AUTOSAR XML (schema 4-2-2)
package /ComponentTypes
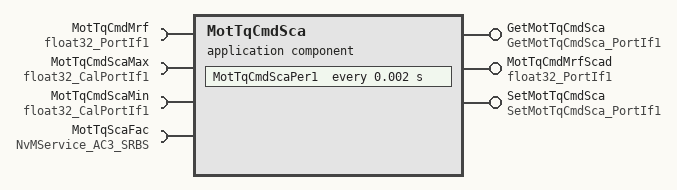
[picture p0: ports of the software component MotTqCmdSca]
  application sw component type MotTqCmdSca
    provide port GetMotTqCmdSca: server-com-spec{operation=Oper, queue-length=1}, provided-interface=GetMotTqCmdSca_PortIf1
    provide port MotTqCmdMrfScad: nonqueued-sender-com-spec{data-element=Val, init-value=0}, provided-interface=float32_PortIf1
    provide port SetMotTqCmdSca: server-com-spec{operation=Oper, queue-length=1}, provided-interface=SetMotTqCmdSca_PortIf1
    4 x require port:
      MotTqCmdMrf: nonqueued-receiver-com-spec{data-element=Val, filter=data-filter-type=ALWAYS, init-value=0}, required-interface=float32_PortIf1
      MotTqCmdScaMax: parameter-require-com-spec{init-value=1.1, parameter=Val}, required-interface=float32_CalPortIf1
      MotTqCmdScaMin: parameter-require-com-spec{init-value=0.9, parameter=Val}, required-interface=float32_CalPortIf1
      MotTqScaFac: required-com-specs=[EraseBlock, GetErrorStatus, InvalidateNvBlock, ReadBlock, SetRamBlockStatus, WriteBlock], required-interface=NvMService_AC3_SRBS
    behavior MotTqCmdSca_InternalBehavior
      ar-typed-per-instance-memorys:
        data MotTqScaFac: sw-calibration-access=READ-ONLY, type=float32
      operation invoked event OIT_GetMotTqCmdSca_Oper_GetMotTqCmdSca_Oper: start-on-event=GetMotTqCmdSca_Oper, operation=GetMotTqCmdSca.Oper
      init event MotTqCmdSca_InitEvent: start-on-event=MotTqCmdScaInit1
      timing event TMT_MotTqCmdScaPer1: start-on-event=MotTqCmdScaPer1, period=0.002
      operation invoked event OIT_SetMotTqCmdSca_Oper_SetMotTqCmdSca_Oper: start-on-event=SetMotTqCmdSca_Oper, operation=SetMotTqCmdSca.Oper
      4 x runnable:
        GetMotTqCmdSca_Oper
        MotTqCmdScaInit1
          sync call SC_MotTqScaFac_GetErrorStatus: operation=MotTqScaFac.GetErrorStatus, timeout=0
          sync call SC_MotTqScaFac_SetRamBlockStatus: operation=MotTqScaFac.SetRamBlockStatus, timeout=0
        MotTqCmdScaPer1: minimum-start-interval=0.002
          data-receive-point-by-arguments:
            access REC_MotTqCmdMrf_Val: accessed-variable=MotTqCmdMrf.Val
          data-send-points:
            access SEND_MotTqCmdMrfScad_Val: accessed-variable=MotTqCmdMrfScad.Val
        SetMotTqCmdSca_Oper
          sync call SC_MotTqScaFac_GetErrorStatus: operation=MotTqScaFac.GetErrorStatus, timeout=0
          sync call SC_MotTqScaFac_SetRamBlockStatus: operation=MotTqScaFac.SetRamBlockStatus, timeout=0
      swc service dependency NvmMotTqScaFac: assigned-datas=role-based-data-assignment={role=ramBlock, used-data-element=MotTqScaFac}, assigned-ports=role-based-port-assignment={port-prototype=MotTqScaFac, role=NvMService_AC3_SRBS}
        service-needs:
          nv block needs NvmMotTqScaFac: n-data-sets=0, ram-block-status-control=API, readonly=false, reliability=ERROR-DETECTION, resistant-to-changed-sw=true, restore-at-start=true, store-at-shutdown=true, write-only-once=false, writing-frequency=0, writing-priority=LOW
  swc implementation MotTqCmdSca_Implementation: behavior=MotTqCmdSca_InternalBehavior
    code-descriptors:
      code Default: artifact-descriptors=autosar-engineering-object={short-label=Default, category=SWSRC}
